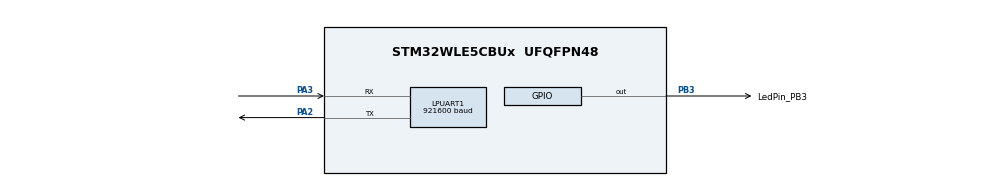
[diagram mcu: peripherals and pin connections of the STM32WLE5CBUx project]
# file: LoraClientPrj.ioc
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FREERTOS.Tasks01=LoraThread,24,128,StartDefaultTask,Default,NULL,Dynamic,NULL,NULL;BlinkThread,8,128,BlinkTask,Default,NULL,Dynamic,NULL,NULL
LPUART1.BaudRate=921600
LPUART1.Mode=UART_MODE_TX
Mcu.Family=STM32WL
Mcu.Name=STM32WLE5CBUx
Mcu.Package=UFQFPN48
NVIC.PriorityGroup=NVIC_PRIORITYGROUP_4
PA2.Mode=Asynchronous
PA2.Signal=LPUART1_TX
PA3.Mode=Asynchronous
PA3.Signal=LPUART1_RX
PB3.GPIO_Label=LedPin_PB3
PB3.Signal=GPIO_Output
ProjectManager.HeapSize=0x200
ProjectManager.StackSize=0x400
ProjectManager.TargetToolchain=STM32CubeIDE
RCC.AHBFreq_Value=4000000
RCC.APB1Freq_Value=4000000
RCC.APB1TimFreq_Value=4000000
RCC.APB2Freq_Value=4000000
RCC.APB2TimFreq_Value=4000000
RCC.APB3Freq_Value=4000000
RCC.CortexFreq_Value=4000000
RCC.HCLKFreq_Value=4000000
RCC.HSE_VALUE=8000000
RCC.HSI_VALUE=16000000
RCC.LPUART1CLockSelection=RCC_LPUART1CLKSOURCE_SYSCLK
RCC.LSE_VALUE=32768
RCC.SYSCLKFreq_VALUE=4000000
RCC.VCOOutputFreq_Value=32000000
VP_ADV_TRACE_VS_ADV_TRACE.Mode=ADV_TRACE_Enabled
VP_FREERTOS_VS_CMSIS_V2.Mode=CMSIS_V2
VP_LORAWAN_VS_LoRaWAN.Mode=LoRaWAN_Enabled
VP_MISC_VS_MISC.Mode=MISC_Enabled
VP_SUBGHZ_VS_SUBGHZ.Mode=SUBGHZ_Activate
VP_TIMER_VS_TIMER.Mode=TIMER_Enabled
VP_TINY_LPM_VS_TINY_LPM.Mode=TINY_LPM_Enabled
board=custom

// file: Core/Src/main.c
/* USER CODE BEGIN Header */
/**
  ******************************************************************************
  * @file           : main.c
  * @brief          : Main program body
  ******************************************************************************
  * @attention
  *
  * Copyright (c) 2022 STMicroelectronics.
  * All rights reserved.
  *
  * This software is licensed under terms that can be found in the LICENSE file
  * in the root directory of this software component.
  * If no LICENSE file comes with this software, it is provided AS-IS.
  *
  ******************************************************************************
  */
/* USER CODE END Header */
#include "main.h"
#include "cmsis_os.h"
#include "app_lorawan.h"
#include "usart.h"
#include "gpio.h"

/* USER CODE BEGIN Includes */
#include "Debug_Log.h"
/* USER CODE END Includes */

void SystemClock_Config(void);
void MX_FREERTOS_Init(void);

/* USER CODE BEGIN 0 */
int fputc(int ch, FILE *f)
{
//    HAL_UART_Transmit(LPUART1, (uint8_t *)&ch, 1, HAL_MAX_DELAY);
    return ch;
}
/* USER CODE END 0 */

int main(void)
{

  /* MCU Configuration--------------------------------------------------------*/

  /* Reset of all peripherals, Initializes the Flash interface and the Systick. */
  HAL_Init();

  /* Configure the system clock */
  SystemClock_Config();

  /* Initialize all configured peripherals */
  MX_GPIO_Init();
  MX_LPUART1_UART_Init();

  /* Init scheduler */
  osKernelInitialize();  /* Call init function for freertos objects (in freertos.c) */
  MX_FREERTOS_Init();

  /* Start scheduler */
  osKernelStart();

  /* We should never get here as control is now taken by the scheduler */
  /* Infinite loop */
  while (1)
  {

  }
}

void SystemClock_Config(void)
{
  RCC_OscInitTypeDef RCC_OscInitStruct = {0};
  RCC_ClkInitTypeDef RCC_ClkInitStruct = {0};

  /** Configure the main internal regulator output voltage
  */
  __HAL_PWR_VOLTAGESCALING_CONFIG(PWR_REGULATOR_VOLTAGE_SCALE2);

  /** Initializes the CPU, AHB and APB buses clocks
  */
  RCC_OscInitStruct.OscillatorType = RCC_OSCILLATORTYPE_MSI;
  RCC_OscInitStruct.MSIState = RCC_MSI_ON;
  RCC_OscInitStruct.MSICalibrationValue = RCC_MSICALIBRATION_DEFAULT;
  RCC_OscInitStruct.MSIClockRange = RCC_MSIRANGE_6;
  RCC_OscInitStruct.PLL.PLLState = RCC_PLL_NONE;
  if (HAL_RCC_OscConfig(&RCC_OscInitStruct) != HAL_OK)
  {
    Error_Handler();
  }

  /** Configure the SYSCLKSource, HCLK, PCLK1 and PCLK2 clocks dividers
  */
  RCC_ClkInitStruct.ClockType = RCC_CLOCKTYPE_HCLK3|RCC_CLOCKTYPE_HCLK
                              |RCC_CLOCKTYPE_SYSCLK|RCC_CLOCKTYPE_PCLK1
                              |RCC_CLOCKTYPE_PCLK2;
  RCC_ClkInitStruct.SYSCLKSource = RCC_SYSCLKSOURCE_MSI;
  RCC_ClkInitStruct.AHBCLKDivider = RCC_SYSCLK_DIV1;
  RCC_ClkInitStruct.APB1CLKDivider = RCC_HCLK_DIV1;
  RCC_ClkInitStruct.APB2CLKDivider = RCC_HCLK_DIV1;
  RCC_ClkInitStruct.AHBCLK3Divider = RCC_SYSCLK_DIV1;

  if (HAL_RCC_ClockConfig(&RCC_ClkInitStruct, FLASH_LATENCY_0) != HAL_OK)
  {
    Error_Handler();
  }
}

void Error_Handler(void)
{
  __disable_irq();
  while (1)
  {
  }
}

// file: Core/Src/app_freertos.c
/* USER CODE BEGIN Header */
/**
  ******************************************************************************
  * File Name          : app_freertos.c
  * Description        : Code for freertos applications
  ******************************************************************************
  * @attention
  *
  * Copyright (c) 2022 STMicroelectronics.
  * All rights reserved.
  *
  * This software is licensed under terms that can be found in the LICENSE file
  * in the root directory of this software component.
  * If no LICENSE file comes with this software, it is provided AS-IS.
  *
  ******************************************************************************
  */
/* USER CODE END Header */

#include "FreeRTOS.h"
#include "task.h"
#include "main.h"
#include "cmsis_os.h"

#include "app_lorawan.h"

/* USER CODE BEGIN Includes */
#include"usart.h"
#include"Debug_Log.h"
/* USER CODE END Includes */

/* Definitions for LoraThread */
osThreadId_t LoraThreadHandle;
const osThreadAttr_t LoraThread_attributes = {
  .name = "LoraThread",
  .priority = (osPriority_t) osPriorityNormal,
  .stack_size = 128 * 4
};
/* Definitions for BlinkThread */
osThreadId_t BlinkThreadHandle;
const osThreadAttr_t BlinkThread_attributes = {
  .name = "BlinkThread",
  .priority = (osPriority_t) osPriorityLow,
  .stack_size = 128 * 4
};

void StartDefaultTask(void *argument);
void BlinkTask(void *argument);

void MX_FREERTOS_Init(void); /* (MISRA C 2004 rule 8.1) */

void MX_FREERTOS_Init(void) {

  /* Create the thread(s) */
  /* creation of LoraThread */
  LoraThreadHandle = osThreadNew(StartDefaultTask, NULL, &LoraThread_attributes);

  /* creation of BlinkThread */
  BlinkThreadHandle = osThreadNew(BlinkTask, NULL, &BlinkThread_attributes);

}

void StartDefaultTask(void *argument)
{
  /* init code for LoRaWAN */
  MX_LoRaWAN_Init();
  for(;;)
  {
    osDelay(1);
  }
}

void BlinkTask(void *argument)
{
  /* USER CODE BEGIN BlinkTask */
  /* Infinite loop */
  for(;;)
  {
	  HAL_GPIO_TogglePin(LedPin_PB3_GPIO_Port, LedPin_PB3_Pin);
	  osDelay(1000);
	  DBG("hello world\r\n");
  }
  /* USER CODE END BlinkTask */
}
